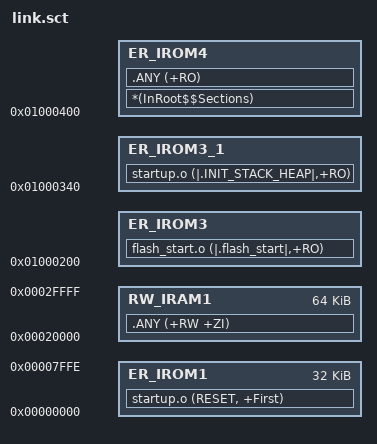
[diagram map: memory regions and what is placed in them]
; *************************************************************
; *** Scatter-Loading Description File generated by uVision ***
; *************************************************************

LR_IROM1 0x00000000 0x0007fff  {    ; load region size_region
  ER_IROM1 0x00000000 0x00007fff  {  ; load address = execution address
   startup.o (RESET, +First)
;   startup.o (.text,+RO)
;   *(InRoot$$Sections)
  }
}

LR_IROM3 0x1000200 0x200{
    ER_IROM3 0x1000200 {
      flash_start.o (|.flash_start|,+RO)
    }
    ER_IROM3_1 0x1000340 {
      startup.o (|.INIT_STACK_HEAP|,+RO)
    }
}

LR_IROM4 0x1000400 0x1000000{
    ER_IROM4 0x1000400 {
      *(InRoot$$Sections)
      .ANY (+RO)
    }

    RW_IRAM1 0x00020000 0x010000  {  ; RW data
    .ANY (+RW +ZI)
    }
}

